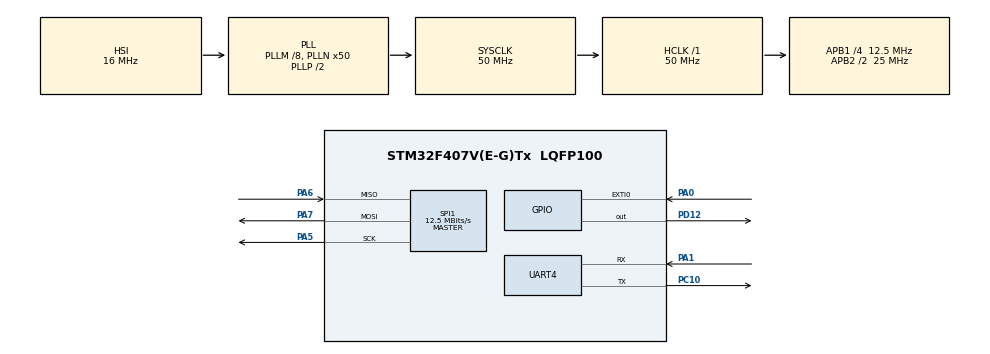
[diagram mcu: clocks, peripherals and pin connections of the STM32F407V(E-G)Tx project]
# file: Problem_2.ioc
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Dma.Request0=SPI1_RX
Dma.Request1=UART4_RX
Dma.SPI1_RX.0.Direction=DMA_PERIPH_TO_MEMORY
Dma.SPI1_RX.0.FIFOMode=DMA_FIFOMODE_DISABLE
Dma.SPI1_RX.0.Instance=DMA2_Stream0
Dma.SPI1_RX.0.MemDataAlignment=DMA_MDATAALIGN_BYTE
Dma.SPI1_RX.0.MemInc=DMA_MINC_ENABLE
Dma.SPI1_RX.0.Mode=DMA_NORMAL
Dma.SPI1_RX.0.PeriphDataAlignment=DMA_PDATAALIGN_BYTE
Dma.SPI1_RX.0.PeriphInc=DMA_PINC_DISABLE
Dma.SPI1_RX.0.Priority=DMA_PRIORITY_LOW
Dma.UART4_RX.1.Direction=DMA_PERIPH_TO_MEMORY
Dma.UART4_RX.1.FIFOMode=DMA_FIFOMODE_DISABLE
Dma.UART4_RX.1.Instance=DMA1_Stream2
Dma.UART4_RX.1.MemDataAlignment=DMA_MDATAALIGN_BYTE
Dma.UART4_RX.1.MemInc=DMA_MINC_ENABLE
Dma.UART4_RX.1.Mode=DMA_NORMAL
Dma.UART4_RX.1.PeriphDataAlignment=DMA_PDATAALIGN_BYTE
Dma.UART4_RX.1.PeriphInc=DMA_PINC_DISABLE
Dma.UART4_RX.1.Priority=DMA_PRIORITY_LOW
Mcu.Family=STM32F4
Mcu.Name=STM32F407V(E-G)Tx
Mcu.Package=LQFP100
NVIC.DMA1_Stream2_IRQn=true\:0\:0\:false\:false\:true\:false\:true\:true
NVIC.DMA2_Stream0_IRQn=true\:0\:0\:false\:false\:true\:false\:true\:true
NVIC.EXTI0_IRQn=true\:0\:0\:false\:false\:true\:true\:true\:true
NVIC.PriorityGroup=NVIC_PRIORITYGROUP_0
PA0-WKUP.Signal=GPXTI0
PA1.Mode=Asynchronous
PA1.Signal=UART4_RX
PA5.Mode=Full_Duplex_Master
PA5.Signal=SPI1_SCK
PA6.Mode=Full_Duplex_Master
PA6.Signal=SPI1_MISO
PA7.Mode=Full_Duplex_Master
PA7.Signal=SPI1_MOSI
PC10.Mode=Asynchronous
PC10.Signal=UART4_TX
PD12.Signal=GPIO_Output
ProjectManager.HeapSize=0x200
ProjectManager.StackSize=0x400
ProjectManager.TargetToolchain=STM32CubeIDE
RCC.48MHZClocksFreq_Value=14285714.285714285
RCC.AHBFreq_Value=50000000
RCC.APB1CLKDivider=RCC_HCLK_DIV4
RCC.APB1Freq_Value=12500000
RCC.APB1TimFreq_Value=25000000
RCC.APB2CLKDivider=RCC_HCLK_DIV2
RCC.APB2Freq_Value=25000000
RCC.APB2TimFreq_Value=50000000
RCC.CortexFreq_Value=50000000
RCC.HCLKFreq_Value=50000000
RCC.HSE_VALUE=8000000
RCC.HSI_VALUE=16000000
RCC.LSE_VALUE=32768
RCC.PLLM=8
RCC.PLLN=50
RCC.PLLQ=7
RCC.SYSCLKFreq_VALUE=50000000
RCC.SYSCLKSource=RCC_SYSCLKSOURCE_PLLCLK
RCC.VCOOutputFreq_Value=100000000
SPI1.CalculateBaudRate=12.5 MBits/s
SPI1.Direction=SPI_DIRECTION_2LINES
SPI1.Mode=SPI_MODE_MASTER
SPI1.VirtualType=VM_MASTER
UART4.VirtualMode=Asynchronous
board=STM32F407G-DISC1

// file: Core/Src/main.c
/* USER CODE BEGIN Header */
/**
  ******************************************************************************
  * @file           : main.c
  * @brief          : Main program body
  ******************************************************************************
  * @attention
  *
  * Copyright (c) 2024 STMicroelectronics.
  * All rights reserved.
  *
  * This software is licensed under terms that can be found in the LICENSE file
  * in the root directory of this software component.
  * If no LICENSE file comes with this software, it is provided AS-IS.
  *
  ******************************************************************************
  */
/* USER CODE END Header */
#include "main.h"
#include "stm32f4xx_hal.h"

SPI_HandleTypeDef hspi1;
DMA_HandleTypeDef hdma_spi1_rx;

UART_HandleTypeDef huart4;
DMA_HandleTypeDef hdma_uart4_rx;

/* USER CODE BEGIN PV */
uint8_t transmit_buffer[]="5";
uint8_t receive_buffer[]="0";
/* USER CODE END PV */

void SystemClock_Config(void);
static void MX_GPIO_Init(void);
static void MX_DMA_Init(void);
static void MX_SPI1_Init(void);
static void MX_UART4_Init(void);

/* USER CODE BEGIN 0 */
//void EXTI0_IRQHandler(void)
//{
//HAL_SPI_Transmit(&hspi1,&transmit_buffer,2,100);
//	__HAL_GPIO_EXTI_CLEAR_IT(GPIO_PIN_0);
//
//}
//
//void DMA1_Stream2_IRQHandler(void)
//{
//	HAL_GPIO_WritePin(GPIOD, GPIO_PIN_12, 1);
//}

void DMA2_Stream0_IRQHandler(void)
{
	HAL_UART_Transmit(&huart4,receive_buffer, sizeof(receive_buffer), 10);
}
/* USER CODE END 0 */

int main(void)
{

  /* MCU Configuration--------------------------------------------------------*/

  /* Reset of all peripherals, Initializes the Flash interface and the Systick. */
  HAL_Init();

  /* Configure the system clock */
  SystemClock_Config();

  /* Initialize all configured peripherals */
  MX_GPIO_Init();
  MX_DMA_Init();
  MX_SPI1_Init();
  MX_UART4_Init();
  /* USER CODE BEGIN 2 */
  SPI_DMAReceiveCplt(&hdma_spi1_rx);

  /* USER CODE END 2 */

  /* Infinite loop */
  while (1)
  {

  }
}

void SystemClock_Config(void)
{
  RCC_OscInitTypeDef RCC_OscInitStruct = {0};
  RCC_ClkInitTypeDef RCC_ClkInitStruct = {0};

  /** Configure the main internal regulator output voltage
  */
  __HAL_RCC_PWR_CLK_ENABLE();
  __HAL_PWR_VOLTAGESCALING_CONFIG(PWR_REGULATOR_VOLTAGE_SCALE1);

  /** Initializes the RCC Oscillators according to the specified parameters
  * in the RCC_OscInitTypeDef structure.
  */
  RCC_OscInitStruct.OscillatorType = RCC_OSCILLATORTYPE_HSI;
  RCC_OscInitStruct.HSIState = RCC_HSI_ON;
  RCC_OscInitStruct.HSICalibrationValue = RCC_HSICALIBRATION_DEFAULT;
  RCC_OscInitStruct.PLL.PLLState = RCC_PLL_ON;
  RCC_OscInitStruct.PLL.PLLSource = RCC_PLLSOURCE_HSI;
  RCC_OscInitStruct.PLL.PLLM = 8;
  RCC_OscInitStruct.PLL.PLLN = 50;
  RCC_OscInitStruct.PLL.PLLP = RCC_PLLP_DIV2;
  RCC_OscInitStruct.PLL.PLLQ = 7;
  if (HAL_RCC_OscConfig(&RCC_OscInitStruct) != HAL_OK)
  {
    Error_Handler();
  }

  /** Initializes the CPU, AHB and APB buses clocks
  */
  RCC_ClkInitStruct.ClockType = RCC_CLOCKTYPE_HCLK|RCC_CLOCKTYPE_SYSCLK
                              |RCC_CLOCKTYPE_PCLK1|RCC_CLOCKTYPE_PCLK2;
  RCC_ClkInitStruct.SYSCLKSource = RCC_SYSCLKSOURCE_PLLCLK;
  RCC_ClkInitStruct.AHBCLKDivider = RCC_SYSCLK_DIV1;
  RCC_ClkInitStruct.APB1CLKDivider = RCC_HCLK_DIV4;
  RCC_ClkInitStruct.APB2CLKDivider = RCC_HCLK_DIV2;

  if (HAL_RCC_ClockConfig(&RCC_ClkInitStruct, FLASH_LATENCY_1) != HAL_OK)
  {
    Error_Handler();
  }
}

static void MX_SPI1_Init(void)
{

  /* SPI1 parameter configuration*/
  hspi1.Instance = SPI1;
  hspi1.Init.Mode = SPI_MODE_MASTER;
  hspi1.Init.Direction = SPI_DIRECTION_2LINES;
  hspi1.Init.DataSize = SPI_DATASIZE_8BIT;
  hspi1.Init.CLKPolarity = SPI_POLARITY_LOW;
  hspi1.Init.CLKPhase = SPI_PHASE_1EDGE;
  hspi1.Init.NSS = SPI_NSS_SOFT;
  hspi1.Init.BaudRatePrescaler = SPI_BAUDRATEPRESCALER_2;
  hspi1.Init.FirstBit = SPI_FIRSTBIT_MSB;
  hspi1.Init.TIMode = SPI_TIMODE_DISABLE;
  hspi1.Init.CRCCalculation = SPI_CRCCALCULATION_DISABLE;
  hspi1.Init.CRCPolynomial = 10;
  if (HAL_SPI_Init(&hspi1) != HAL_OK)
  {
    Error_Handler();
  }

}

static void MX_UART4_Init(void)
{

  huart4.Instance = UART4;
  huart4.Init.BaudRate = 115200;
  huart4.Init.WordLength = UART_WORDLENGTH_8B;
  huart4.Init.StopBits = UART_STOPBITS_1;
  huart4.Init.Parity = UART_PARITY_NONE;
  huart4.Init.Mode = UART_MODE_TX_RX;
  huart4.Init.HwFlowCtl = UART_HWCONTROL_NONE;
  huart4.Init.OverSampling = UART_OVERSAMPLING_16;
  if (HAL_UART_Init(&huart4) != HAL_OK)
  {
    Error_Handler();
  }

}

static void MX_DMA_Init(void)
{

  /* DMA controller clock enable */
  __HAL_RCC_DMA2_CLK_ENABLE();
  __HAL_RCC_DMA1_CLK_ENABLE();

  /* DMA interrupt init */
  /* DMA1_Stream2_IRQn interrupt configuration */
  HAL_NVIC_SetPriority(DMA1_Stream2_IRQn, 0, 0);
  HAL_NVIC_EnableIRQ(DMA1_Stream2_IRQn);
  /* DMA2_Stream0_IRQn interrupt configuration */
  HAL_NVIC_SetPriority(DMA2_Stream0_IRQn, 0, 0);
  HAL_NVIC_EnableIRQ(DMA2_Stream0_IRQn);

}

static void MX_GPIO_Init(void)
{
  GPIO_InitTypeDef GPIO_InitStruct = {0};

  /* GPIO Ports Clock Enable */
  __HAL_RCC_GPIOA_CLK_ENABLE();
  __HAL_RCC_GPIOD_CLK_ENABLE();
  __HAL_RCC_GPIOC_CLK_ENABLE();

  /*Configure GPIO pin Output Level */
  HAL_GPIO_WritePin(GPIOD, GPIO_PIN_12, GPIO_PIN_RESET);

  /*Configure GPIO pin : PA0 */
  GPIO_InitStruct.Pin = GPIO_PIN_0;
  GPIO_InitStruct.Mode = GPIO_MODE_IT_RISING;
  GPIO_InitStruct.Pull = GPIO_NOPULL;
  HAL_GPIO_Init(GPIOA, &GPIO_InitStruct);

  /*Configure GPIO pin : PD12 */
  GPIO_InitStruct.Pin = GPIO_PIN_12;
  GPIO_InitStruct.Mode = GPIO_MODE_OUTPUT_PP;
  GPIO_InitStruct.Pull = GPIO_NOPULL;
  GPIO_InitStruct.Speed = GPIO_SPEED_FREQ_LOW;
  HAL_GPIO_Init(GPIOD, &GPIO_InitStruct);

  /* EXTI interrupt init*/
  HAL_NVIC_SetPriority(EXTI0_IRQn, 0, 0);
  HAL_NVIC_EnableIRQ(EXTI0_IRQn);

}

void Error_Handler(void)
{
  __disable_irq();
  while (1)
  {
  }
}
